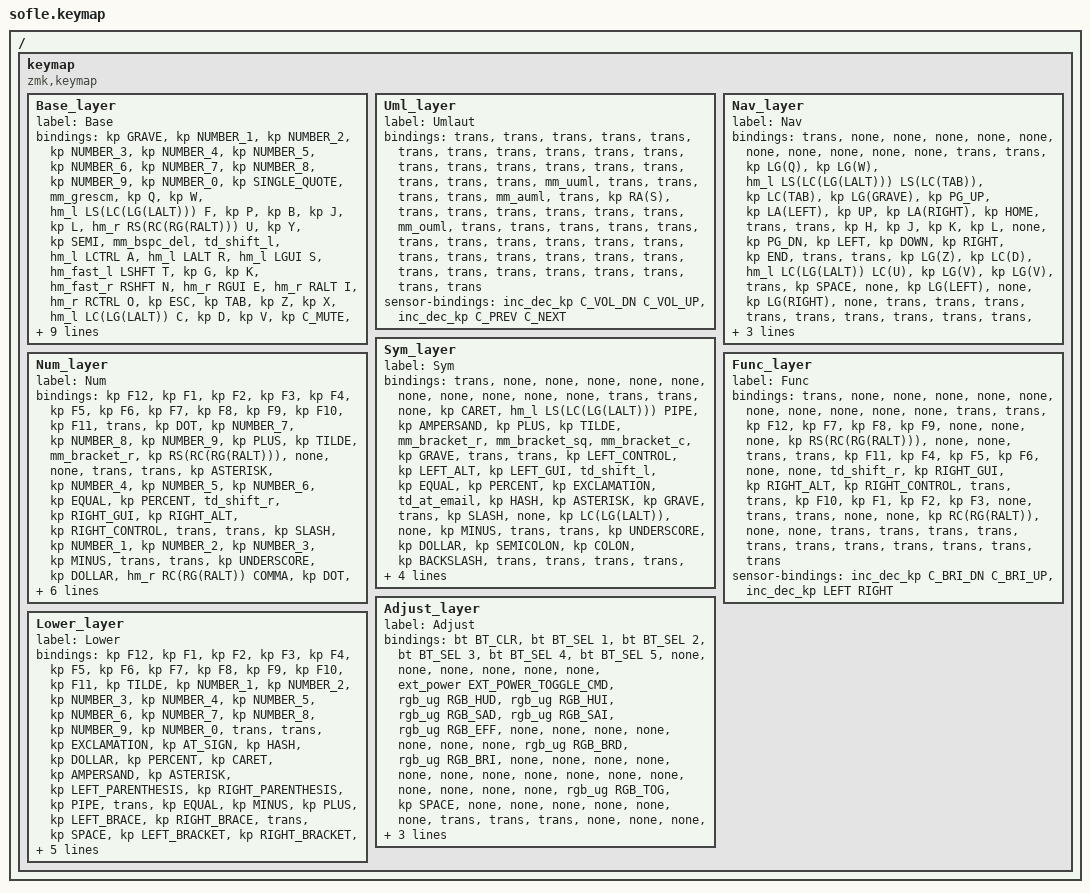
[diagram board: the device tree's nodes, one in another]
/*
 * Copyright (c) 2020 The ZMK Contributors
 *
 * SPDX-License-Identifier: MIT
 */

// Define layer numbers
#define BASE 0
#define UML 1
#define NAV 2
#define SYM 3
#define NUM 4
#define FUNC 5
#define ADJUST 6
#define LOWER 7


// ZMK includes
#include <behaviors.dtsi>
#include <dt-bindings/zmk/keys.h>
#include <dt-bindings/zmk/bt.h>
#include <dt-bindings/zmk/rgb.h>
#include <dt-bindings/zmk/ext_power.h>

// Personal includes
#include "includes/settings.dtsi"
#include "includes/settings_pd.dtsi"
#include "includes/conditional_layers.dtsi"
#include "includes/macros.dtsi"
#include "includes/combos.dtsi"
#include "includes/behaviours_homerow_mods.dtsi"
#include "includes/behaviours_mod_morph.dtsi"
#include "includes/behaviours_other.dtsi"


/ {

  /*
   * Keymap generated using https://www.keymapper.dev/
   * Import sofle_keymap.json to view it.
   */

  keymap {
    compatible = "zmk,keymap";

    Base_layer {
      label = "Base";
      bindings = <
        &kp GRAVE &kp NUMBER_1 &kp NUMBER_2 &kp NUMBER_3 &kp NUMBER_4 &kp NUMBER_5 &kp NUMBER_6 &kp NUMBER_7 &kp NUMBER_8 &kp NUMBER_9 &kp NUMBER_0 &kp SINGLE_QUOTE &mm_grescm &kp Q &kp W &hm_l LS(LC(LG(LALT))) F &kp P &kp B &kp J &kp L &hm_r RS(RC(RG(RALT))) U &kp Y &kp SEMI &mm_bspc_del &td_shift_l &hm_l LCTRL A &hm_l LALT R &hm_l LGUI S &hm_fast_l LSHFT T &kp G &kp K &hm_fast_r RSHFT N &hm_r RGUI E &hm_r RALT I &hm_r RCTRL O &kp ESC &kp TAB &kp Z &kp X &hm_l LC(LG(LALT)) C &kp D &kp V &kp C_MUTE &kp C_PLAY_PAUSE &kp M &kp H &hm_r RC(RG(RALT)) COMMA &kp DOT &kp SLASH &td_shift_r &kp LEFT_CONTROL &kp LEFT_ALT &mm_grescm_gui &mm_spc_unds_layer &lt SYM TAB &mm_bspc_del_layer &lt UML RETURN &td_shift_r &kp RIGHT_GUI &kp RIGHT_ALT
      >;
      sensor-bindings = <&inc_dec_kp C_VOL_DN C_VOL_UP &inc_dec_kp C_PREV C_NEXT>;
    };
    Uml_layer {
      label = "Umlaut";
      bindings = <
        &trans &trans &trans &trans  &trans  &trans  &trans  &trans  &trans  &trans  &trans  &trans  &trans &trans  &trans  &trans &trans  &trans  &trans  &trans  &mm_uuml &trans  &trans  &trans &trans  &mm_auml &trans &kp RA(S) &trans &trans  &trans  &trans &trans &trans &mm_ouml &trans  &trans &trans  &trans  &trans &trans  &trans  &trans  &trans  &trans  &trans  &trans &trans  &trans  &trans &trans  &trans  &trans &trans &trans &trans &trans  &trans &trans  &trans 
      >;
      sensor-bindings = <&inc_dec_kp C_VOL_DN C_VOL_UP &inc_dec_kp C_PREV C_NEXT>;
    };

    Nav_layer {
      label = "Nav";
      bindings = < &trans &none &none &none &none &none &none &none &none &none &none &trans &trans &kp LG(Q) &kp LG(W) &hm_l LS(LC(LG(LALT))) LS(LC(TAB)) &kp LC(TAB) &kp LG(GRAVE) &kp PG_UP &kp LA(LEFT) &kp UP &kp LA(RIGHT) &kp HOME &trans &trans &kp H &kp J &kp K &kp L &none &kp PG_DN &kp LEFT &kp DOWN &kp RIGHT &kp END &trans &trans &kp LG(Z) &kp LC(D) &hm_l LC(LG(LALT)) LC(U) &kp LG(V) &kp LG(V) &trans &kp SPACE &none &kp LG(LEFT) &none &kp LG(RIGHT) &none &trans &trans &trans &trans &trans &trans &trans &trans &trans &trans &trans >;
      sensor-bindings = <&inc_dec_kp C_BRI_DN C_BRI_UP &inc_dec_kp LEFT RIGHT>;
    };

    Sym_layer {
      label = "Sym";
      bindings = <
        &trans &none &none &none &none &none &none &none &none &none &none &trans &trans &none &kp CARET &hm_l LS(LC(LG(LALT))) PIPE &kp AMPERSAND &kp PLUS &kp TILDE &mm_bracket_r &mm_bracket_sq &mm_bracket_c &kp GRAVE &trans &trans &kp LEFT_CONTROL &kp LEFT_ALT &kp LEFT_GUI &td_shift_l &kp EQUAL &kp PERCENT &kp EXCLAMATION &td_at_email &kp HASH &kp ASTERISK &kp GRAVE &trans &kp SLASH &none &kp LC(LG(LALT)) &none &kp MINUS &trans &trans &kp UNDERSCORE &kp DOLLAR &kp SEMICOLON &kp COLON &kp BACKSLASH &trans &trans &trans &trans &trans &trans &trans &trans &trans &trans &trans
      >;
      sensor-bindings = <&inc_dec_kp C_BRI_DN C_BRI_UP &inc_dec_kp LEFT RIGHT>;
    };

    Num_layer {
      label = "Num";
      bindings = <
        &kp F12 &kp F1 &kp F2 &kp F3 &kp F4 &kp F5 &kp F6 &kp F7 &kp F8 &kp F9 &kp F10 &kp F11 &trans &kp DOT &kp NUMBER_7 &kp NUMBER_8 &kp NUMBER_9 &kp PLUS &kp TILDE &mm_bracket_r &kp RS(RC(RG(RALT))) &none &none &trans &trans &kp ASTERISK &kp NUMBER_4 &kp NUMBER_5 &kp NUMBER_6 &kp EQUAL &kp PERCENT &td_shift_r &kp RIGHT_GUI &kp RIGHT_ALT &kp RIGHT_CONTROL &trans &trans &kp SLASH &kp NUMBER_1 &kp NUMBER_2 &kp NUMBER_3 &kp MINUS &trans &trans &kp UNDERSCORE &kp DOLLAR &hm_r RC(RG(RALT)) COMMA &kp DOT &kp SLASH &trans &trans &kp LEFT_PARENTHESIS &hm LGUI RIGHT_PARENTHESIS &trans &kp NUMBER_0 &trans &trans &trans &trans &trans
      >;
      sensor-bindings = <&inc_dec_kp C_BRI_DN C_BRI_UP &inc_dec_kp LEFT RIGHT>;
    };

    Func_layer {
      label = "Func";
      bindings = <
        &trans &none &none &none &none &none &none &none &none &none &none &trans &trans &kp F12 &kp F7 &kp F8 &kp F9 &none &none &none &kp RS(RC(RG(RALT))) &none &none &trans &trans &kp F11 &kp F4 &kp F5 &kp F6 &none &none &td_shift_r &kp RIGHT_GUI &kp RIGHT_ALT &kp RIGHT_CONTROL &trans &trans &kp F10 &kp F1 &kp F2 &kp F3 &none &trans &trans &none &none &kp RC(RG(RALT)) &none &none &trans &trans &trans &trans &trans &trans &trans &trans &trans &trans &trans
      >;
      sensor-bindings = <&inc_dec_kp C_BRI_DN C_BRI_UP &inc_dec_kp LEFT RIGHT>;
    };

    Adjust_layer {
      label = "Adjust";
      bindings = <
        &bt BT_CLR &bt BT_SEL 1 &bt BT_SEL 2 &bt BT_SEL 3 &bt BT_SEL 4 &bt BT_SEL 5 &none &none &none &none &none &none &ext_power EXT_POWER_TOGGLE_CMD &rgb_ug RGB_HUD &rgb_ug RGB_HUI &rgb_ug RGB_SAD &rgb_ug RGB_SAI &rgb_ug RGB_EFF &none &none &none &none &none &none &none &rgb_ug RGB_BRD &rgb_ug RGB_BRI &none &none &none &none &none &none &none &none &none &none &none &none &none &none &none &rgb_ug RGB_TOG &kp SPACE &none &none &none &none &none &none &trans &trans &trans &none &none &none &none &none &none &none
      >;
      sensor-bindings = <&inc_dec_kp C_BRI_DN C_BRI_UP &inc_dec_kp LEFT RIGHT>;
    };

    Lower_layer {
      label = "Lower";
      bindings = <
        &kp F12 &kp F1 &kp F2 &kp F3 &kp F4 &kp F5 &kp F6 &kp F7 &kp F8 &kp F9 &kp F10 &kp F11 &kp TILDE &kp NUMBER_1 &kp NUMBER_2 &kp NUMBER_3 &kp NUMBER_4 &kp NUMBER_5 &kp NUMBER_6 &kp NUMBER_7 &kp NUMBER_8 &kp NUMBER_9 &kp NUMBER_0 &trans &trans &kp EXCLAMATION &kp AT_SIGN &kp HASH &kp DOLLAR &kp PERCENT &kp CARET &kp AMPERSAND &kp ASTERISK &kp LEFT_PARENTHESIS &kp RIGHT_PARENTHESIS &kp PIPE &trans &kp EQUAL &kp MINUS &kp PLUS &kp LEFT_BRACE &kp RIGHT_BRACE &trans &kp SPACE &kp LEFT_BRACKET &kp RIGHT_BRACKET &kp SEMICOLON &kp COLON &kp BACKSLASH &trans &trans &trans &trans &kp UNDERSCORE &kp TILDE &kp DEL &trans &trans &trans &trans
      >;
      sensor-bindings = <&inc_dec_kp C_BRI_DN C_BRI_UP &inc_dec_kp LEFT RIGHT>;
    };
  };

};
